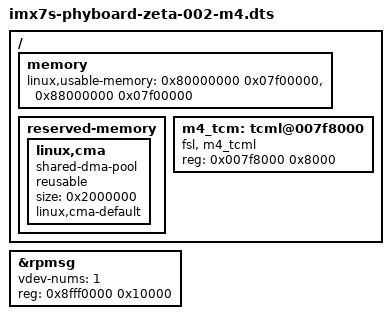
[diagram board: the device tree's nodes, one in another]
/*
 * Copyright (C) 2017 PHYTEC America, LLC
 *
 * This program is free software; you can redistribute it and/or modify
 * it under the terms of the GNU General Public License version 2 as
 * published by the Free Software Foundation.
 */

#include "imx7s-phyboard-zeta-002.dts"
#include "imx7-phyboard-zeta-m4.dtsi"

/ {
	/* usable memory */
	memory {
		/* 2 128MB ddr, reserve last MB for RPMSG FreeRTOS */
		linux,usable-memory = <0x80000000 0x07f00000>,
				      <0x88000000 0x07f00000>;
	};

	reserved-memory {
		#address-cells = <1>;
		#size-cells = <1>;
		ranges;

		/* global autoconfigured region for contiguous allocations */
		linux,cma {
			compatible = "shared-dma-pool";
			reusable;
			size = <0x2000000>;
			linux,cma-default;
		};
	};

	m4_tcm: tcml@007f8000 {
		compatible = "fsl, m4_tcml";
		reg = <0x007f8000 0x8000>;
	};
};

&rpmsg {
	/* rpmsg vring stored at end of memory */
	vdev-nums = <1>;
	reg = <0x8fff0000 0x10000>;
	status = "okay";
};
